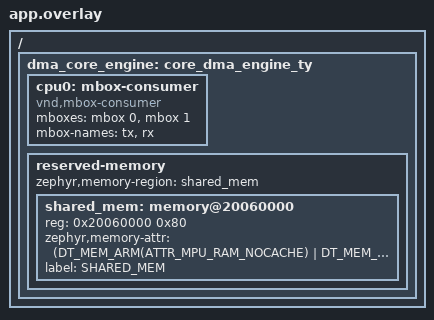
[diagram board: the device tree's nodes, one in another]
#include <zephyr/dt-bindings/memory-attr/memory-attr.h>
#include <zephyr/dt-bindings/memory-attr/memory-attr-arm.h>

/ {

	dma_core_engine: core_dma_engine_ty {
		cpu0: mbox-consumer {
			compatible = "vnd,mbox-consumer";
			mboxes = <&mbox 0>, <&mbox 1>;
			mbox-names = "tx", "rx";
		};

		reserved-memory {
			#address-cells = <1>;
			#size-cells = <1>;
			zephyr,memory-region = "shared_mem";
			shared_mem: memory@20060000 {
				reg = <0x20060000 0x80>;
				zephyr,memory-attr = <(DT_MEM_ARM(ATTR_MPU_RAM_NOCACHE) | DT_MEM_ARM(ATTR_MPU_IO))>;
				label = "SHARED_MEM";
			};
		};
	};
};

